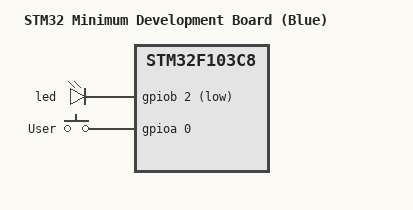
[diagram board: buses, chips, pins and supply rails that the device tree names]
/*
 * Copyright (c) 2017, embedjournal.com
 *
 * SPDX-License-Identifier: Apache-2.0
 */

/ {
	model = "STM32 Minimum Development Board (Blue)";
	compatible = "stm32_min_dev_blue", "st,stm32f103c8";

	leds {
		led: led {
			gpios = <&gpiob 2 GPIO_ACTIVE_LOW>;
		};
	};

	gpio_keys {
		compatible = "gpio-keys";
		user_button: button {
			label = "User";
			gpios = <&gpioa 0 (GPIO_ACTIVE_HIGH | GPIO_PULL_DOWN)>;
			zephyr,code = <INPUT_KEY_0>;
		};
	};

	aliases {
		sw0 = &user_button;
	};

};
